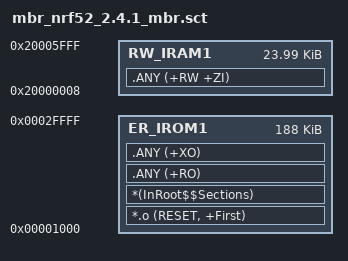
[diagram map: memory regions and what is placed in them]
; *************************************************************
; *** Scatter-Loading Description File generated by uVision ***
; *************************************************************

LR_IROM1 0x00001000 0x0002F000  {    ; load region size_region
  ER_IROM1 0x00001000 0x0002F000  {  ; load address = execution address
   *.o (RESET, +First)
   *(InRoot$$Sections)
   .ANY (+RO)
   .ANY (+XO)
  }
  RW_IRAM1 0x20000008 0x00005FF8  {  ; RW data
   .ANY (+RW +ZI)
  }
}

